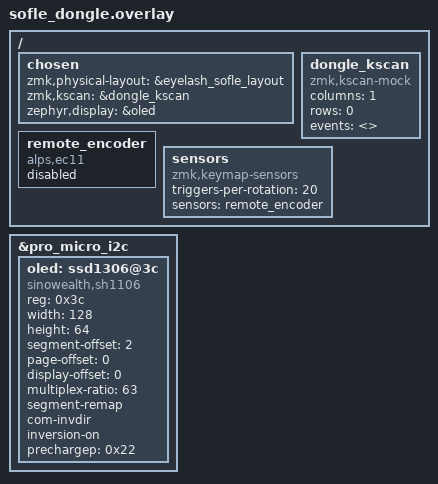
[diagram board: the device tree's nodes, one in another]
#include "../eyelash_sofle/eyelash_sofle-logical.dtsi"

/ {
    chosen {
        zmk,physical-layout = &eyelash_sofle_layout;
        zmk,kscan = &dongle_kscan;
        zephyr,display = &oled;
    };

    dongle_kscan: dongle_kscan {
        compatible = "zmk,kscan-mock";
        columns = <1>;
        rows = <0>;
        events = <>;
    };

    remote_encoder: remote_encoder {
        compatible = "alps,ec11";
        status = "disabled";
    };

    sensors {
        compatible = "zmk,keymap-sensors";
        triggers-per-rotation = <20>;
        sensors = <&remote_encoder>;
    };
};

&pro_micro_i2c {
    status = "okay";
    oled: ssd1306@3c {
        compatible = "sinowealth,sh1106";
        reg = <0x3c>;
        width = <128>;
        height = <64>;
        segment-offset = <2>;
        page-offset = <0>;
        display-offset = <0>;
        multiplex-ratio = <63>;
        segment-remap;
        com-invdir;
        inversion-on;
        prechargep = <0x22>;
    };
};
